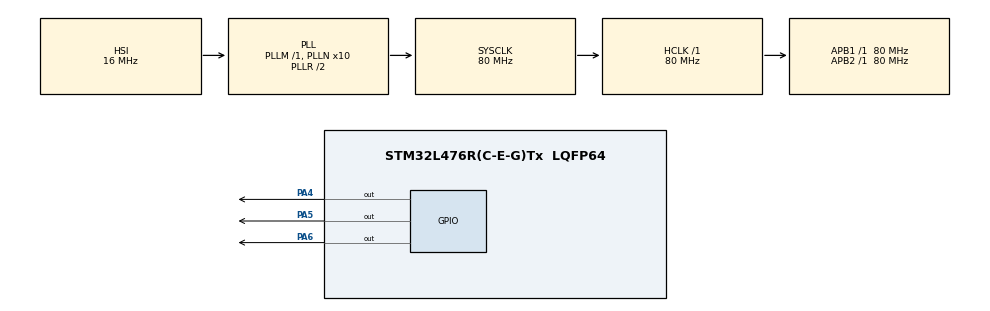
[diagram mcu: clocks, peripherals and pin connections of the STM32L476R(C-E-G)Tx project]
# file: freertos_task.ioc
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FREERTOS.Tasks01=defaultTask,0,128,StartDefaultTask,Default,NULL,Dynamic,NULL,NULL;LED,-3,128,task1_LED,Default,NULL,Dynamic,NULL,NULL;LED_RED,-3,128,RED_LED,Default,NULL,Dynamic,NULL,NULL
FREERTOS.configUSE_NEWLIB_REENTRANT=1
Mcu.Family=STM32L4
Mcu.Name=STM32L476R(C-E-G)Tx
Mcu.Package=LQFP64
NVIC.PriorityGroup=NVIC_PRIORITYGROUP_4
PA4.Signal=GPIO_Output
PA5.Signal=GPIO_Output
PA6.Signal=GPIO_Output
ProjectManager.HeapSize=0x200
ProjectManager.StackSize=0x400
ProjectManager.TargetToolchain=STM32CubeIDE
RCC.ADCFreq_Value=64000000
RCC.AHBFreq_Value=80000000
RCC.APB1Freq_Value=80000000
RCC.APB1TimFreq_Value=80000000
RCC.APB2Freq_Value=80000000
RCC.APB2TimFreq_Value=80000000
RCC.CortexFreq_Value=80000000
RCC.HCLKFreq_Value=80000000
RCC.HSE_VALUE=8000000
RCC.HSI_VALUE=16000000
RCC.LSE_VALUE=32768
RCC.MSI_VALUE=4000000
RCC.PLLN=10
RCC.PLLSourceVirtual=RCC_PLLSOURCE_HSI
RCC.PREFETCH_ENABLE=1
RCC.SYSCLKFreq_VALUE=80000000
RCC.SYSCLKSource=RCC_SYSCLKSOURCE_PLLCLK
RCC.USBFreq_Value=64000000
RCC.VCOOutputFreq_Value=160000000
VP_FREERTOS_VS_CMSIS_V1.Mode=CMSIS_V1
board=NUCLEO-L476RG

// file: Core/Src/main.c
/* USER CODE BEGIN Header */
/**
  ******************************************************************************
  * @file           : main.c
  * @brief          : Main program body
  ******************************************************************************
  * @attention
  *
  * Copyright (c) 2023 STMicroelectronics.
  * All rights reserved.
  *
  * This software is licensed under terms that can be found in the LICENSE file
  * in the root directory of this software component.
  * If no LICENSE file comes with this software, it is provided AS-IS.
  *
  ******************************************************************************
  */
/* USER CODE END Header */
#include "main.h"
#include "cmsis_os.h"
#include "stdio.h"
/* USER CODE BEGIN Includes */
int _write(int file,char *ptr,int len)
{
    int i=0;
    for(i=0;i<len;i++)
    	ITM_SendChar((*ptr++));
    return len;
}
/* USER CODE END Includes */

osThreadId defaultTaskHandle;
osThreadId LEDHandle;
osThreadId LED_REDHandle;

void SystemClock_Config(void);
static void MX_GPIO_Init(void);
void StartDefaultTask(void const * argument);
void task1_LED(void const * argument);
void RED_LED(void const * argument);

int main(void)
{

  /* MCU Configuration--------------------------------------------------------*/

  /* Reset of all peripherals, Initializes the Flash interface and the Systick. */
  HAL_Init();

  /* Configure the system clock */
  SystemClock_Config();

  /* Initialize all configured peripherals */
  MX_GPIO_Init();

  /* Create the thread(s) */
  /* definition and creation of defaultTask */
  osThreadDef(defaultTask, StartDefaultTask, osPriorityNormal, 0, 128);
  defaultTaskHandle = osThreadCreate(osThread(defaultTask), NULL);

  /* definition and creation of LED */
  osThreadDef(LED, task1_LED, 1, 0, 128);
  LEDHandle = osThreadCreate(osThread(LED), NULL);

  /* definition and creation of LED_RED */
  osThreadDef(LED_RED, RED_LED, 2, 0, 128);
  LED_REDHandle = osThreadCreate(osThread(LED_RED), NULL);

  /* Start scheduler */
  osKernelStart();
  /* We should never get here as control is now taken by the scheduler */
  /* Infinite loop */
  while (1)
  {

  }
}

void SystemClock_Config(void)
{
  RCC_OscInitTypeDef RCC_OscInitStruct = {0};
  RCC_ClkInitTypeDef RCC_ClkInitStruct = {0};

  /** Configure the main internal regulator output voltage
  */
  if (HAL_PWREx_ControlVoltageScaling(PWR_REGULATOR_VOLTAGE_SCALE1) != HAL_OK)
  {
    Error_Handler();
  }

  /** Initializes the RCC Oscillators according to the specified parameters
  * in the RCC_OscInitTypeDef structure.
  */
  RCC_OscInitStruct.OscillatorType = RCC_OSCILLATORTYPE_HSI;
  RCC_OscInitStruct.HSIState = RCC_HSI_ON;
  RCC_OscInitStruct.HSICalibrationValue = RCC_HSICALIBRATION_DEFAULT;
  RCC_OscInitStruct.PLL.PLLState = RCC_PLL_ON;
  RCC_OscInitStruct.PLL.PLLSource = RCC_PLLSOURCE_HSI;
  RCC_OscInitStruct.PLL.PLLM = 1;
  RCC_OscInitStruct.PLL.PLLN = 10;
  RCC_OscInitStruct.PLL.PLLP = RCC_PLLP_DIV7;
  RCC_OscInitStruct.PLL.PLLQ = RCC_PLLQ_DIV2;
  RCC_OscInitStruct.PLL.PLLR = RCC_PLLR_DIV2;
  if (HAL_RCC_OscConfig(&RCC_OscInitStruct) != HAL_OK)
  {
    Error_Handler();
  }

  /** Initializes the CPU, AHB and APB buses clocks
  */
  RCC_ClkInitStruct.ClockType = RCC_CLOCKTYPE_HCLK|RCC_CLOCKTYPE_SYSCLK
                              |RCC_CLOCKTYPE_PCLK1|RCC_CLOCKTYPE_PCLK2;
  RCC_ClkInitStruct.SYSCLKSource = RCC_SYSCLKSOURCE_PLLCLK;
  RCC_ClkInitStruct.AHBCLKDivider = RCC_SYSCLK_DIV1;
  RCC_ClkInitStruct.APB1CLKDivider = RCC_HCLK_DIV1;
  RCC_ClkInitStruct.APB2CLKDivider = RCC_HCLK_DIV1;

  if (HAL_RCC_ClockConfig(&RCC_ClkInitStruct, FLASH_LATENCY_4) != HAL_OK)
  {
    Error_Handler();
  }
}

static void MX_GPIO_Init(void)
{
  GPIO_InitTypeDef GPIO_InitStruct = {0};

  /* GPIO Ports Clock Enable */
  __HAL_RCC_GPIOA_CLK_ENABLE();

  /*Configure GPIO pin Output Level */
  HAL_GPIO_WritePin(GPIOA, GPIO_PIN_4|GPIO_PIN_5|GPIO_PIN_6, GPIO_PIN_RESET);

  /*Configure GPIO pins : PA4 PA5 PA6 */
  GPIO_InitStruct.Pin = GPIO_PIN_4|GPIO_PIN_5|GPIO_PIN_6;
  GPIO_InitStruct.Mode = GPIO_MODE_OUTPUT_PP;
  GPIO_InitStruct.Pull = GPIO_NOPULL;
  GPIO_InitStruct.Speed = GPIO_SPEED_FREQ_LOW;
  HAL_GPIO_Init(GPIOA, &GPIO_InitStruct);

}

void StartDefaultTask(void const * argument)
{
  /* USER CODE BEGIN 5 */
  /* Infinite loop */
  for(;;)
  {
	  HAL_GPIO_TogglePin(GPIOA,GPIO_PIN_5);
	  //HAL_GPIO_WritePin(GPIOA,GPIO_PIN_5, SET);
	  printf("Difault task is running\n");
	  printf("PA5 is blink\n");
    osDelay(100);
  }
  /* USER CODE END 5 */
}

void task1_LED(void const * argument)
{
  /* USER CODE BEGIN task1_LED */
  /* Infinite loop */
  for(;;)
  {
	  HAL_GPIO_TogglePin(GPIOA,6);
	  	  printf("LED task is running\n");
	  	  printf("PA6 is blink\n");
    osDelay(100);
  }
  /* USER CODE END task1_LED */
}

void RED_LED(void const * argument)
{
  /* USER CODE BEGIN RED_LED */
  /* Infinite loop */
  for(;;)
  {
	  HAL_GPIO_TogglePin(GPIOA,4);
	  	  printf("RED_LED task is running\n");
	  	  printf("PA4 is blink\n");
    osDelay(100);
  }
  /* USER CODE END RED_LED */
}

void Error_Handler(void)
{
  __disable_irq();
  while (1)
  {
  }
}
